VERSION ""

NS_ :

BS_:

BU_: WX110

BO_ 2516388387 PressureData: 8 WX110
 SG_ AtmPressurePrecise_kpa : 24|32@1+ (0.0001,0) [0|429496.7295] "kpa" Vector__XXX

BO_ 2315059747 WindData: 5 WX110
 SG_ WindSpeed_mps : 8|16@1+ (0.01,0) [0|655.35] "m/s" Vector__XXX
 SG_ WindDirection_rad : 24|16@1+ (0.0001,0) [0|6.5535] "rad" Vector__XXX

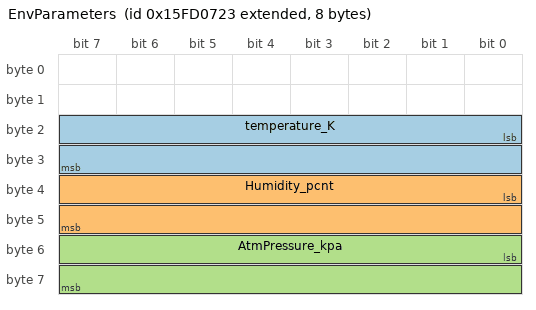
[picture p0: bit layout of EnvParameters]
BO_ 2516387619 EnvParameters: 8 WX110
 SG_ temperature_K : 16|16@1+ (0.01,0) [0|655.35] "K" Vector__XXX
 SG_ Humidity_pcnt : 32|16@1- (0.004,0) [-131.072|131.068] "%" Vector__XXX
 SG_ AtmPressure_kpa : 48|16@1+ (0.1,0) [0|6553.5] "kpa" Vector__XXX

BA_DEF_ SG_  "SigType" ENUM  "Default","Range","RangeSigned","ASCII","Discrete","Control","ReferencePGN","DTC","StringDelimiter","StringLength","StringLengthControl","MessageCounter","MessageChecksum";
BA_DEF_ SG_  "GenSigEVName" STRING ;
BA_DEF_ SG_  "GenSigILSupport" ENUM  "No","Yes";
BA_DEF_ SG_  "GenSigSendType" ENUM  "Cyclic","OnWrite","OnWriteWithRepetition","OnChange","OnChangeWithRepetition","IfActive","IfActiveWithRepetition","NoSigSendType";
BA_DEF_ BO_  "GenMsgILSupport" ENUM  "No","Yes";
BA_DEF_ BU_  "NmStationAddress" INT 0 255;
BA_DEF_ BO_  "GenMsgSendType" ENUM  "cyclic","NotUsed","IfActive","NotUsed","NotUsed","NotUsed","NotUsed","NotUsed","noMsgSendType";
BA_DEF_ BO_  "GenMsgRequestable" INT 0 1;
BA_DEF_  "DBName" STRING ;
BA_DEF_  "BusType" STRING ;
BA_DEF_  "ProtocolType" STRING ;
BA_DEF_ BO_  "VFrameFormat" ENUM  "StandardCAN","ExtendedCAN","reserved","J1939PG";
BA_DEF_DEF_  "SigType" "Default";
BA_DEF_DEF_  "GenSigEVName" "Env@Nodename_@Signame";
BA_DEF_DEF_  "GenSigILSupport" "Yes";
BA_DEF_DEF_  "GenSigSendType" "NoSigSendType";
BA_DEF_DEF_  "GenMsgILSupport" "Yes";
BA_DEF_DEF_  "NmStationAddress" 254;
BA_DEF_DEF_  "GenMsgSendType" "noMsgSendType";
BA_DEF_DEF_  "GenMsgRequestable" 1;
BA_DEF_DEF_  "DBName" "";
BA_DEF_DEF_  "BusType" "CAN";
BA_DEF_DEF_  "ProtocolType" "J1939";
BA_DEF_DEF_  "VFrameFormat" "J1939PG";
BA_ "ProtocolType" "";
BA_ "DBName" "Node_Wx110_j1939";
BA_ "NmStationAddress" BU_ WX110 35;
